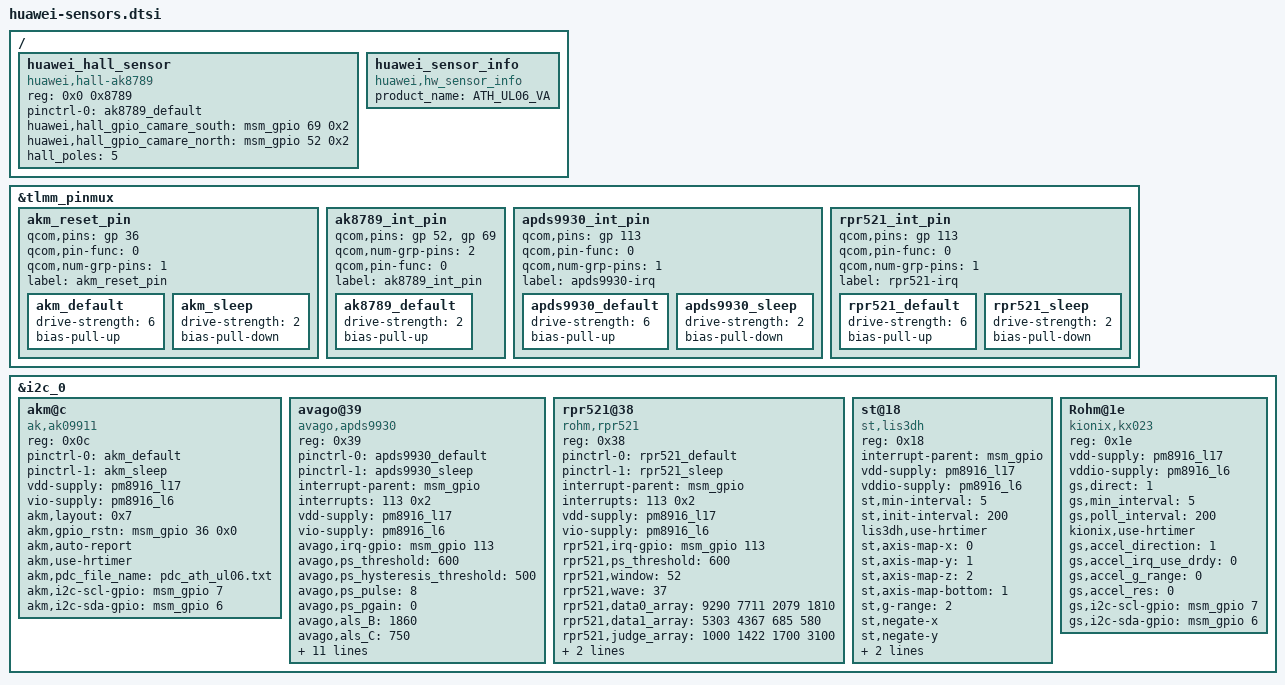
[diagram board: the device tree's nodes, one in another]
/* < DTS2014121804508 wangcunyou 20141218 begin */
/*use fromdos convert file format to linux*/
/* Copyright (c) 2013 The Linux Foundation. All rights reserved.
 *
 * This program is free software; you can redistribute it and/or modify
 * it under the terms of the GNU General Public License version 2 and
 * only version 2 as published by the Free Software Foundation.
 *
 * This program is distributed in the hope that it will be useful,
 * but WITHOUT ANY WARRANTY; without even the implied warranty of
 * MERCHANTABILITY or FITNESS FOR A PARTICULAR PURPOSE.  See the
 * GNU General Public License for more details.
 */
&tlmm_pinmux {
	akm_reset_pin {
		qcom,pins = <&gp 36>;
		qcom,pin-func = <0>;
		qcom,num-grp-pins = <1>;
		label = "akm_reset_pin";
		akm_default: akm_default {
			drive-strength = <6>;
			bias-pull-up;
		};
		akm_sleep: akm_sleep {
			drive-strength = <2>;
			bias-pull-down;
		};
	};

/* DTS2015012910874 dingjingfeng 20150206 begin> */
//delete lines
/* DTS2015012910874 dingjingfeng 20150206 end> */
	ak8789_int_pin {
		qcom,pins = <&gp 52>, <&gp 69>;
		qcom,num-grp-pins = <2>;
		qcom,pin-func = <0>;
		label = "ak8789_int_pin";
		ak8789_default: ak8789_default {
			  drive-strength = <2>;
			  bias-pull-up;
		};
	};
	apds9930_int_pin {
		qcom,pins = <&gp 113>;
		qcom,pin-func = <0>;
		qcom,num-grp-pins = <1>;
		label = "apds9930-irq";
		apds9930_default: apds9930_default {
			drive-strength = <6>;
			bias-pull-up;
		};
		apds9930_sleep: apds9930_sleep {
			drive-strength = <2>;
			bias-pull-down;
		};
	};
	/* < DTS2015010600226 wangcunyou 20140106 begin */
	rpr521_int_pin {
		qcom,pins = <&gp 113>;
		qcom,pin-func = <0>;
		qcom,num-grp-pins = <1>;
		label = "rpr521-irq";
		rpr521_default: rpr521_default {
			drive-strength = <6>;
			bias-pull-up;
		};
		rpr521_sleep: rpr521_sleep {
			drive-strength = <2>;
			bias-pull-down;
		};
	};
	/* DTS2015010600226 wangcunyou 20140106 end > */
};

&i2c_0 { /* BLSP1 QUP2 */
	akm@c {
		compatible = "ak,ak09911";
		reg = <0x0c>;
		pinctrl-names = "default","sleep";
		pinctrl-0 = <&akm_default>;
		pinctrl-1 = <&akm_sleep>;
		vdd-supply = <&pm8916_l17>;
		vio-supply = <&pm8916_l6>;
		akm,layout = <0x7>;
		akm,gpio_rstn = <&msm_gpio 36 0x0>;
		akm,auto-report;
		/* < DTS2015052009130 hufeng 20150601 begin */
		akm,use-hrtimer;
		/*  DTS2015052009130 hufeng 20150601 end > */
		/* < DTS2015032800844 caowei 20150319 begin */
		akm,pdc_file_name = "pdc_ath_ul06.txt";
		akm,i2c-scl-gpio = <&msm_gpio 7 0x0>;
		akm,i2c-sda-gpio = <&msm_gpio 6 0x0>;
		/* DTS2015032800844 caowei 20150319 end > */
	};

	avago@39 {
		compatible = "avago,apds9930";
		reg = <0x39>;
		pinctrl-names = "default","sleep";
		pinctrl-0 = <&apds9930_default>;
		pinctrl-1 = <&apds9930_sleep>;
		interrupt-parent = <&msm_gpio>;
		interrupts = <113 0x2>;
		vdd-supply = <&pm8916_l17>;
		vio-supply = <&pm8916_l6>;
		avago,irq-gpio = <&msm_gpio 113 0x2>;
		avago,ps_threshold = <600>;
		avago,ps_hysteresis_threshold = <500>;
		avago,ps_pulse = <8>;
		avago,ps_pgain = <0>;
		avago,als_B = <1860>;
		avago,als_C = <750>;
		avago,als_D = <1290>;
		avago,ga_value = <48>;
	        avago,ga_a_value = <112>;
		avago,ga_c_value = <450>;
		avago,ga_d_value = <162>;
		avago,window = <110>;
		avago,wave = <84>;
		avago,ga_e_value = <220>;
		avago,ga_f_value = <43>;
		/* < DTS2015032800844 caowei 20150319 begin */
		avago,i2c-scl-gpio = <&msm_gpio 7 0x0>;
		avago,i2c-sda-gpio = <&msm_gpio 6 0x0>;
		/* DTS2015032800844 caowei 20150319 end > */
	};
	/* < DTS2015010600226 wangcunyou 20140106 begin */
	rpr521@38 {
		compatible = "rohm,rpr521";
		reg = <0x38>;
		pinctrl-names = "default","sleep";
		pinctrl-0 = <&rpr521_default>;
		pinctrl-1 = <&rpr521_sleep>;
		interrupt-parent = <&msm_gpio>;
		interrupts = <113 0x2>;
		vdd-supply = <&pm8916_l17>;
		vio-supply = <&pm8916_l6>;
		rpr521,irq-gpio = <&msm_gpio 113 0x2>;
		rpr521,ps_threshold = <600>;
		/* < DTS2014092001161  zhangyonggang 20140920 begin */
		rpr521,window = <52>;
		rpr521,wave = <37>;
		rpr521,data0_array = <9290 7711 2079 1810>; 
		rpr521,data1_array = <5303 4367 685 580>;   
		rpr521,judge_array = <1000 1422 1700 3100>;
		/* < DTS2014092001161  zhangyonggang 20140920 end > */
		/* < DTS2015032800844 caowei 20150319 begin */
		rpr521,i2c-scl-gpio = <&msm_gpio 7 0x0>;
		rpr521,i2c-sda-gpio = <&msm_gpio 6 0x0>;
		/* DTS2015032800844 caowei 20150319 end > */
	};
	/* DTS2015010600226 wangcunyou 20140106 end > */

	st@18 {
		compatible = "st,lis3dh";
		reg = <0x18>;
/* DTS2015012910874 dingjingfeng 20150206 begin> */
//delete lines
/* DTS2015012910874 dingjingfeng 20150206 end> */
		interrupt-parent = <&msm_gpio>;
		vdd-supply = <&pm8916_l17>;
		vddio-supply = <&pm8916_l6>;
		st,min-interval = <5>;
		st,init-interval = <200>;
		/*  DTS2015052009130 hufeng 20150601 end > */
		lis3dh,use-hrtimer;
		/* < DTS2015052009130 hufeng 20150601 begin */
		st,axis-map-x = <0>;
		st,axis-map-y = <1>;
		st,axis-map-z = <2>;
		/*1 is bottom and others means top*/
		st,axis-map-bottom=<1>;
		st,g-range = <2>;
/* DTS2015012910874 dingjingfeng 20150206 begin> */
//delete lines
/* DTS2015012910874 dingjingfeng 20150206 end> */
		st,negate-x;
		st,negate-y;
		/* < DTS2015032800844 caowei 20150319 begin */
		st,i2c-scl-gpio = <&msm_gpio 7 0x0>;
		st,i2c-sda-gpio = <&msm_gpio 6 0x0>;
		/* DTS2015032800844 caowei 20150319 end > */
	};
	Rohm@1e {
		compatible = "kionix,kx023";
		reg = <0x1e>;
/* DTS2015012910874 dingjingfeng 20150206 begin> */
//delete lines
/* DTS2015012910874 dingjingfeng 20150206 end> */
		vdd-supply = <&pm8916_l17>;
		vddio-supply = <&pm8916_l6>;
		/* < DTS2014042813729 yangzhonghua 20140428 begin */
/* DTS2015012910874 dingjingfeng 20150206 begin> */
//delete lines
/* DTS2015012910874 dingjingfeng 20150206 end> */
		/* DTS2014042813729  yangzhonghua 20140428 end > */
		/* < DTS2014102905500 chuguoliang 20141029 begin */
		/*1 is bottom and others means top*/
		gs,direct = <1>;
		/* DTS2014102905500 chuguoliang 20141029 end > */
		gs,min_interval = <5>;
		gs,poll_interval = <200>;
		/* < DTS2015052009130 hufeng 20150601 begin */
		kionix,use-hrtimer;
		/*  DTS2015052009130 hufeng 20150601 end > */
		gs,accel_direction = <1>;
		gs,accel_irq_use_drdy = <0>;
		gs,accel_g_range = <0>;
		gs,accel_res = <0>;
		/* < DTS2015032800844 caowei 20150319 begin */
		gs,i2c-scl-gpio = <&msm_gpio 7 0x0>;
		gs,i2c-sda-gpio = <&msm_gpio 6 0x0>;
		/* DTS2015032800844 caowei 20150319 end > */
	};
};
/{
	huawei_hall_sensor{
		compatible = "huawei,hall-ak8789";
		reg = <0x0 0x8789>;
		pinctrl-names = "default";
		pinctrl-0 = <&ak8789_default>;
		/* < DTS2014122304450 wangcunyou 20141223 begin */
		huawei,hall_gpio_camare_south = <&msm_gpio 69 0x2>;
		huawei,hall_gpio_camare_north = <&msm_gpio 52 0x2>;
		hall_poles = <5>;
		/* DTS2014122304450 wangcunyou 20141222 end > */
		status = "ok";
	};
};
/* DTS2014121804508 wangcunyou 20141218 end > */
/* < DTS2015020511013 wangcunyou 20150205 begin */
/{
	huawei_sensor_info {
		compatible = "huawei,hw_sensor_info";
		product_name = "ATH_UL06_VA";
	};
};
/* DTS2015020511013 wangcunyou 20150205 end > */
